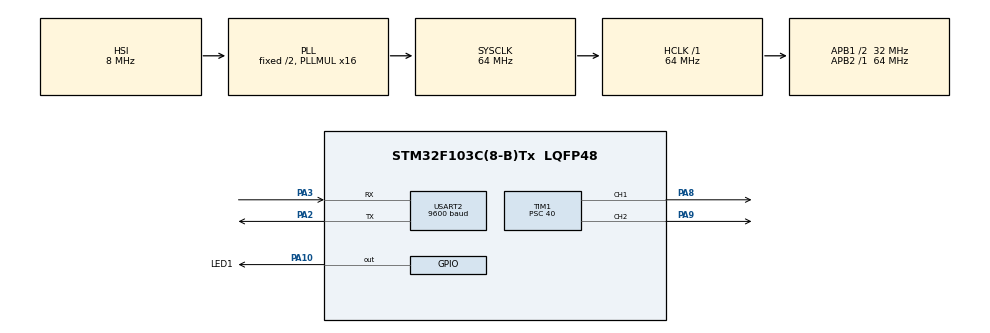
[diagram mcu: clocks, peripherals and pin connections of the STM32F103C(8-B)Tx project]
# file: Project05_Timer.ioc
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Mcu.Family=STM32F1
Mcu.Name=STM32F103C(8-B)Tx
Mcu.Package=LQFP48
NVIC.PriorityGroup=NVIC_PRIORITYGROUP_2
NVIC.TIM2_IRQn=true\:0\:0\:false\:false\:true\:true\:true
NVIC.USART2_IRQn=true\:0\:0\:true\:false\:true\:true\:true
PA10.GPIO_Label=LED1
PA10.Signal=GPIO_Output
PA13.Mode=Serial_Wire
PA13.Signal=SYS_JTMS-SWDIO
PA14.Mode=Serial_Wire
PA14.Signal=SYS_JTCK-SWCLK
PA2.Mode=Asynchronous
PA2.Signal=USART2_TX
PA3.Mode=Asynchronous
PA3.Signal=USART2_RX
PA8.Signal=S_TIM1_CH1
PA9.Signal=S_TIM1_CH2
ProjectManager.HeapSize=0x200
ProjectManager.StackSize=0x400
ProjectManager.TargetToolchain=MDK-ARM V5
RCC.AHBFreq_Value=64000000
RCC.APB1CLKDivider=RCC_HCLK_DIV2
RCC.APB1Freq_Value=32000000
RCC.APB1TimFreq_Value=64000000
RCC.APB2Freq_Value=64000000
RCC.APB2TimFreq_Value=64000000
RCC.HCLKFreq_Value=64000000
RCC.PLLMUL=RCC_PLL_MUL16
RCC.SYSCLKFreq_VALUE=64000000
RCC.SYSCLKSource=RCC_SYSCLKSOURCE_PLLCLK
RCC.USBFreq_Value=64000000
SH.S_TIM1_CH1.0=TIM1_CH1,PWM Generation1 CH1
SH.S_TIM1_CH2.0=TIM1_CH2,Output Compare2 CH2
TIM1.Channel-Output\ Compare2\ CH2=TIM_CHANNEL_2
TIM1.Channel-PWM\ Generation1\ CH1=TIM_CHANNEL_1
TIM1.Period=100
TIM1.Prescaler=40
TIM2.Period=1000
TIM2.Prescaler=6399
USART2.BaudRate=9600
USART2.VirtualMode=VM_ASYNC
VP_TIM1_VS_ClockSourceINT.Mode=Internal
VP_TIM2_VS_ClockSourceINT.Mode=Internal
board=custom

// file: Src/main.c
/* USER CODE BEGIN Header */
/**
  ******************************************************************************
  * @file           : main.c
  * @brief          : Main program body
  ******************************************************************************
  * @attention
  *
  * <h2><center>&copy; Copyright (c) 2021 STMicroelectronics.
  * All rights reserved.</center></h2>
  *
  * This software component is licensed by ST under BSD 3-Clause license,
  * the "License"; You may not use this file except in compliance with the
  * License. You may obtain a copy of the License at:
  *                        opensource.org/licenses/BSD-3-Clause
  *
  ******************************************************************************
  */
/* USER CODE END Header */

#include "main.h"
#include "tim.h"
#include "usart.h"
#include "gpio.h"

void SystemClock_Config(void);

int main(void)
{

  /* MCU Configuration--------------------------------------------------------*/

  /* Reset of all peripherals, Initializes the Flash interface and the Systick. */
  HAL_Init();

  /* Configure the system clock */
  SystemClock_Config();

  /* Initialize all configured peripherals */
  MX_GPIO_Init();
  MX_TIM1_Init();
  MX_TIM2_Init();
  MX_USART2_UART_Init();
  /* USER CODE BEGIN 2 */

    HAL_TIM_Base_Start_IT(&htim2); // 启动定时器2的中断服务程序

  /* USER CODE END 2 */

  /* Infinite loop */
  while (1)
  {

  }
}

void SystemClock_Config(void)
{
  RCC_OscInitTypeDef RCC_OscInitStruct = {0};
  RCC_ClkInitTypeDef RCC_ClkInitStruct = {0};

  /** Initializes the CPU, AHB and APB busses clocks
  */
  RCC_OscInitStruct.OscillatorType = RCC_OSCILLATORTYPE_HSI;
  RCC_OscInitStruct.HSIState = RCC_HSI_ON;
  RCC_OscInitStruct.HSICalibrationValue = RCC_HSICALIBRATION_DEFAULT;
  RCC_OscInitStruct.PLL.PLLState = RCC_PLL_ON;
  RCC_OscInitStruct.PLL.PLLSource = RCC_PLLSOURCE_HSI_DIV2;
  RCC_OscInitStruct.PLL.PLLMUL = RCC_PLL_MUL16;
  if (HAL_RCC_OscConfig(&RCC_OscInitStruct) != HAL_OK)
  {
    Error_Handler();
  }
  /** Initializes the CPU, AHB and APB busses clocks
  */
  RCC_ClkInitStruct.ClockType = RCC_CLOCKTYPE_HCLK|RCC_CLOCKTYPE_SYSCLK
                              |RCC_CLOCKTYPE_PCLK1|RCC_CLOCKTYPE_PCLK2;
  RCC_ClkInitStruct.SYSCLKSource = RCC_SYSCLKSOURCE_PLLCLK;
  RCC_ClkInitStruct.AHBCLKDivider = RCC_SYSCLK_DIV1;
  RCC_ClkInitStruct.APB1CLKDivider = RCC_HCLK_DIV2;
  RCC_ClkInitStruct.APB2CLKDivider = RCC_HCLK_DIV1;

  if (HAL_RCC_ClockConfig(&RCC_ClkInitStruct, FLASH_LATENCY_2) != HAL_OK)
  {
    Error_Handler();
  }
}

void Error_Handler(void)
{
}

/************************ (C) COPYRIGHT STMicroelectronics *****END OF FILE****/
